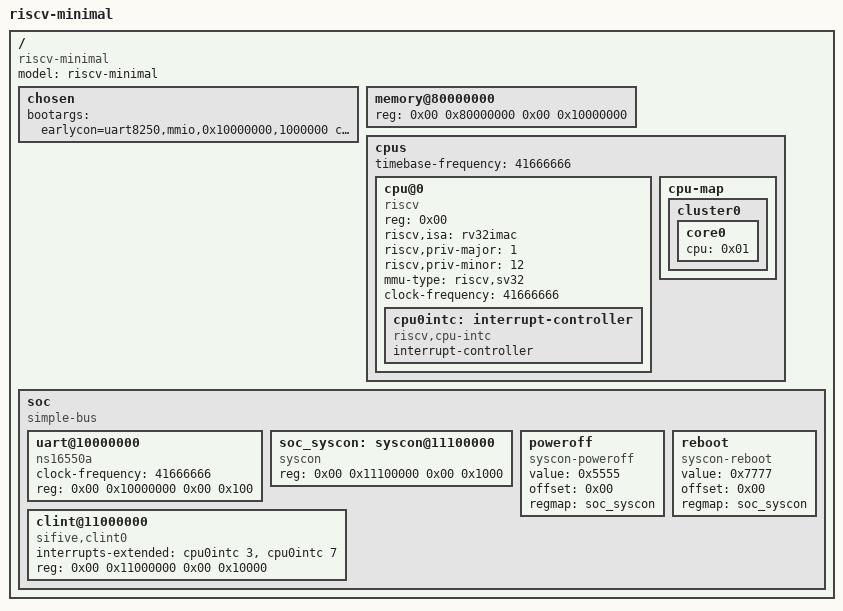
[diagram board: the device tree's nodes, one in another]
/dts-v1/;

/ {
	#address-cells = <0x02>;
	#size-cells = <0x02>;
	compatible = "riscv-minimal";
	model = "riscv-minimal";

	chosen {
		bootargs = "earlycon=uart8250,mmio,0x10000000,1000000 console=ttyS0";
	};

	memory@80000000 {
		device_type = "memory";
		reg = <0x00 0x80000000 0x00 0x10000000>;
	};

	cpus {
		#address-cells = <0x01>;
		#size-cells = <0x00>;
		timebase-frequency = <41666666>;

		cpu@0 {
			phandle = <0x01>;
			device_type = "cpu";
			reg = <0x00>;
			status = "okay";
			compatible = "riscv";
			riscv,isa = "rv32imac";
			riscv,priv-major = <1>;
			riscv,priv-minor = <12>;
			mmu-type = "riscv,sv32";
			clock-frequency = <41666666>;

			cpu0intc: interrupt-controller {
				#interrupt-cells = <0x01>;
				interrupt-controller;
				compatible = "riscv,cpu-intc";
				phandle = <2>;
			};
		};

		cpu-map {

			cluster0 {

				core0 {
					cpu = <0x01>;
				};
			};
		};
	};

	soc {
		#address-cells = <0x02>;
		#size-cells = <0x02>;
		compatible = "simple-bus";
		ranges;

		uart@10000000 {
			clock-frequency = <41666666>;
			reg = <0x00 0x10000000 0x00 0x100>;
			compatible = "ns16550a";
            //interrupt-parent = <&cpu0intc>;
            //interrupts = <5>;
		};

        soc_syscon: syscon@11100000 {
			phandle = <0x04>;
			reg = <0x00 0x11100000 0x00 0x1000>;
			compatible = "syscon";
		};

		poweroff {
			value = <0x5555>;
			offset = <0x00>;
			regmap = <&soc_syscon>;
			compatible = "syscon-poweroff";
		};

		reboot {
			value = <0x7777>;
			offset = <0x00>;
			regmap = <&soc_syscon>;
			compatible = "syscon-reboot";
		};

		clint@11000000 {
			interrupts-extended = <&cpu0intc 3>,  <&cpu0intc 7>;
			reg = <0x00 0x11000000 0x00 0x10000>;
			compatible = "sifive,clint0\0riscv,clint0";
		};
	};
};
